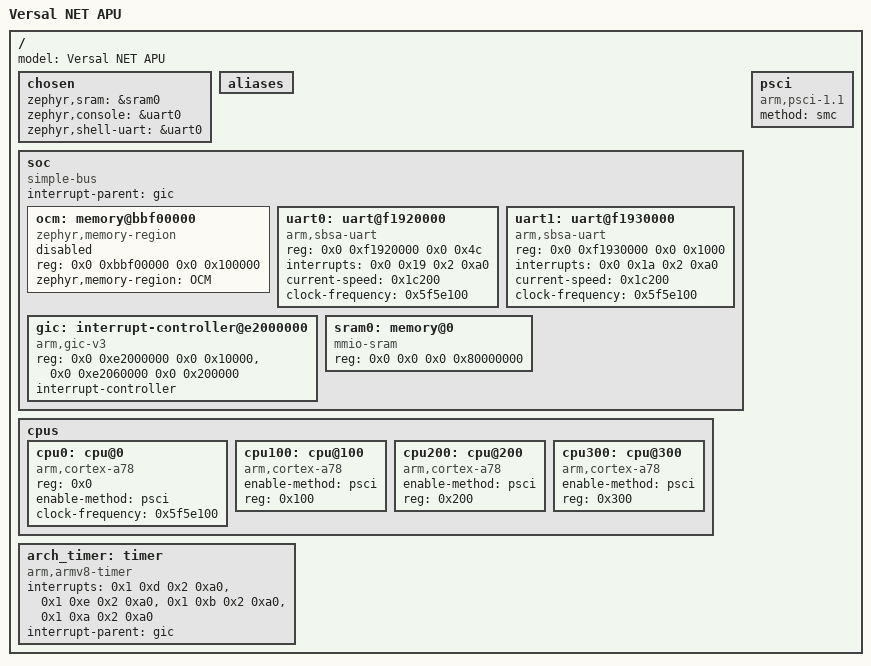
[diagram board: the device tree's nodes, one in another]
/dts-v1/;

/* node '/' defined in zephyr/dts/common/skeleton.dtsi:9 */
/ {
	model = "Versal NET APU"; /* in zephyr/dts/arm64/xilinx/versalnet_a78.dtsi:15 */
	#address-cells = < 0x2 >; /* in zephyr/dts/arm64/xilinx/versalnet_a78.dtsi:16 */
	#size-cells = < 0x2 >;    /* in zephyr/dts/arm64/xilinx/versalnet_a78.dtsi:17 */

	/* node '/chosen' defined in zephyr/dts/common/skeleton.dtsi:13 */
	chosen {
		zephyr,sram = &sram0;       /* in zephyr/boards/amd/versalnet_apu/versalnet_apu.dts:12 */
		zephyr,console = &uart0;    /* in zephyr/boards/amd/versalnet_apu/versalnet_apu.dts:13 */
		zephyr,shell-uart = &uart0; /* in zephyr/boards/amd/versalnet_apu/versalnet_apu.dts:14 */
	};

	/* node '/aliases' defined in zephyr/dts/common/skeleton.dtsi:15 */
	aliases {
	};

	/* node '/soc' defined in zephyr/dts/arm64/armv8-a.dtsi:10 */
	soc: soc {
		compatible = "simple-bus";   /* in zephyr/dts/arm64/armv8-a.dtsi:13 */
		ranges;                      /* in zephyr/dts/arm64/armv8-a.dtsi:14 */
		#address-cells = < 0x2 >;    /* in zephyr/dts/vendor/amd/versalnet_apu.dtsi:9 */
		#size-cells = < 0x2 >;       /* in zephyr/dts/vendor/amd/versalnet_apu.dtsi:10 */
		interrupt-parent = < &gic >; /* in zephyr/dts/arm64/xilinx/versalnet_a78.dtsi:68 */

		/* node '/soc/memory@bbf00000' defined in zephyr/dts/vendor/amd/versalnet_apu.dtsi:17 */
		ocm: memory@bbf00000 {
			compatible = "zephyr,memory-region";   /* in zephyr/dts/vendor/amd/versalnet_apu.dtsi:18 */
			reg = < 0x0 0xbbf00000 0x0 0x100000 >; /* in zephyr/dts/vendor/amd/versalnet_apu.dtsi:19 */
			status = "disabled";                   /* in zephyr/dts/vendor/amd/versalnet_apu.dtsi:20 */
			zephyr,memory-region = "OCM";          /* in zephyr/dts/vendor/amd/versalnet_apu.dtsi:21 */
		};

		/* node '/soc/uart@f1920000' defined in zephyr/dts/vendor/amd/versalnet_apu.dtsi:24 */
		uart0: uart@f1920000 {
			compatible = "arm,sbsa-uart";       /* in zephyr/dts/vendor/amd/versalnet_apu.dtsi:25 */
			reg = < 0x0 0xf1920000 0x0 0x4c >;  /* in zephyr/dts/vendor/amd/versalnet_apu.dtsi:26 */
			interrupt-names = "irq_0";          /* in zephyr/dts/vendor/amd/versalnet_apu.dtsi:28 */
			interrupts = < 0x0 0x19 0x2 0xa0 >; /* in zephyr/dts/vendor/amd/versalnet_apu.dtsi:29 */
			status = "okay";                    /* in zephyr/boards/amd/versalnet_apu/versalnet_apu.dts:36 */
			current-speed = < 0x1c200 >;        /* in zephyr/boards/amd/versalnet_apu/versalnet_apu.dts:37 */
			clock-frequency = < 0x5f5e100 >;    /* in zephyr/boards/amd/versalnet_apu/versalnet_apu.dts:38 */
		};

		/* node '/soc/uart@f1930000' defined in zephyr/dts/vendor/amd/versalnet_apu.dtsi:32 */
		uart1: uart@f1930000 {
			compatible = "arm,sbsa-uart";        /* in zephyr/dts/vendor/amd/versalnet_apu.dtsi:33 */
			reg = < 0x0 0xf1930000 0x0 0x1000 >; /* in zephyr/dts/vendor/amd/versalnet_apu.dtsi:34 */
			interrupt-names = "irq_1";           /* in zephyr/dts/vendor/amd/versalnet_apu.dtsi:36 */
			interrupts = < 0x0 0x1a 0x2 0xa0 >;  /* in zephyr/dts/vendor/amd/versalnet_apu.dtsi:37 */
			status = "okay";                     /* in zephyr/boards/amd/versalnet_apu/versalnet_apu.dts:30 */
			current-speed = < 0x1c200 >;         /* in zephyr/boards/amd/versalnet_apu/versalnet_apu.dts:31 */
			clock-frequency = < 0x5f5e100 >;     /* in zephyr/boards/amd/versalnet_apu/versalnet_apu.dts:32 */
		};

		/* node '/soc/interrupt-controller@e2000000' defined in zephyr/dts/arm64/xilinx/versalnet_a78.dtsi:70 */
		gic: interrupt-controller@e2000000 {
			compatible = "arm,gic-v3",
			             "arm,gic";                /* in zephyr/dts/arm64/xilinx/versalnet_a78.dtsi:71 */
			reg = < 0x0 0xe2000000 0x0 0x10000 >,
			      < 0x0 0xe2060000 0x0 0x200000 >; /* in zephyr/dts/arm64/xilinx/versalnet_a78.dtsi:72 */
			interrupt-controller;                  /* in zephyr/dts/arm64/xilinx/versalnet_a78.dtsi:74 */
			#interrupt-cells = < 0x4 >;            /* in zephyr/dts/arm64/xilinx/versalnet_a78.dtsi:75 */
			#address-cells = < 0x1 >;              /* in zephyr/dts/arm64/xilinx/versalnet_a78.dtsi:76 */
			#size-cells = < 0x1 >;                 /* in zephyr/dts/arm64/xilinx/versalnet_a78.dtsi:77 */
			phandle = < 0x1 >;                     /* in zephyr/dts/arm64/xilinx/versalnet_a78.dtsi:68 */
		};

		/* node '/soc/memory@0' defined in zephyr/boards/amd/versalnet_apu/versalnet_apu.dts:23 */
		sram0: memory@0 {
			compatible = "mmio-sram";         /* in zephyr/boards/amd/versalnet_apu/versalnet_apu.dts:24 */
			reg = < 0x0 0x0 0x0 0x80000000 >; /* in zephyr/boards/amd/versalnet_apu/versalnet_apu.dts:25 */
		};
	};

	/* node '/cpus' defined in zephyr/dts/arm64/xilinx/versalnet_a78.dtsi:19 */
	cpus {
		#address-cells = < 0x1 >; /* in zephyr/dts/arm64/xilinx/versalnet_a78.dtsi:20 */
		#size-cells = < 0x0 >;    /* in zephyr/dts/arm64/xilinx/versalnet_a78.dtsi:21 */

		/* node '/cpus/cpu@0' defined in zephyr/dts/arm64/xilinx/versalnet_a78.dtsi:23 */
		cpu0: cpu@0 {
			device_type = "cpu";             /* in zephyr/dts/arm64/xilinx/versalnet_a78.dtsi:24 */
			compatible = "arm,cortex-a78";   /* in zephyr/dts/arm64/xilinx/versalnet_a78.dtsi:25 */
			reg = < 0x0 >;                   /* in zephyr/dts/arm64/xilinx/versalnet_a78.dtsi:26 */
			enable-method = "psci";          /* in zephyr/dts/arm64/xilinx/versalnet_a78.dtsi:27 */
			clock-frequency = < 0x5f5e100 >; /* in zephyr/boards/amd/versalnet_apu/versalnet_apu.dts:19 */
		};

		/* node '/cpus/cpu@100' defined in zephyr/dts/arm64/xilinx/versalnet_a78.dtsi:30 */
		cpu100: cpu@100 {
			device_type = "cpu";           /* in zephyr/dts/arm64/xilinx/versalnet_a78.dtsi:31 */
			compatible = "arm,cortex-a78"; /* in zephyr/dts/arm64/xilinx/versalnet_a78.dtsi:32 */
			enable-method = "psci";        /* in zephyr/dts/arm64/xilinx/versalnet_a78.dtsi:33 */
			reg = < 0x100 >;               /* in zephyr/dts/arm64/xilinx/versalnet_a78.dtsi:34 */
		};

		/* node '/cpus/cpu@200' defined in zephyr/dts/arm64/xilinx/versalnet_a78.dtsi:37 */
		cpu200: cpu@200 {
			device_type = "cpu";           /* in zephyr/dts/arm64/xilinx/versalnet_a78.dtsi:38 */
			compatible = "arm,cortex-a78"; /* in zephyr/dts/arm64/xilinx/versalnet_a78.dtsi:39 */
			enable-method = "psci";        /* in zephyr/dts/arm64/xilinx/versalnet_a78.dtsi:40 */
			reg = < 0x200 >;               /* in zephyr/dts/arm64/xilinx/versalnet_a78.dtsi:41 */
		};

		/* node '/cpus/cpu@300' defined in zephyr/dts/arm64/xilinx/versalnet_a78.dtsi:44 */
		cpu300: cpu@300 {
			device_type = "cpu";           /* in zephyr/dts/arm64/xilinx/versalnet_a78.dtsi:45 */
			compatible = "arm,cortex-a78"; /* in zephyr/dts/arm64/xilinx/versalnet_a78.dtsi:46 */
			enable-method = "psci";        /* in zephyr/dts/arm64/xilinx/versalnet_a78.dtsi:47 */
			reg = < 0x300 >;               /* in zephyr/dts/arm64/xilinx/versalnet_a78.dtsi:48 */
		};
	};

	/* node '/psci' defined in zephyr/dts/arm64/xilinx/versalnet_a78.dtsi:52 */
	psci {
		compatible = "arm,psci-1.1"; /* in zephyr/dts/arm64/xilinx/versalnet_a78.dtsi:53 */
		method = "smc";              /* in zephyr/dts/arm64/xilinx/versalnet_a78.dtsi:54 */
	};

	/* node '/timer' defined in zephyr/dts/arm64/xilinx/versalnet_a78.dtsi:57 */
	arch_timer: timer {
		compatible = "arm,armv8-timer";    /* in zephyr/dts/arm64/xilinx/versalnet_a78.dtsi:58 */
		interrupts = < 0x1 0xd 0x2 0xa0 >,
		             < 0x1 0xe 0x2 0xa0 >,
		             < 0x1 0xb 0x2 0xa0 >,
		             < 0x1 0xa 0x2 0xa0 >; /* in zephyr/dts/arm64/xilinx/versalnet_a78.dtsi:59 */
		interrupt-parent = < &gic >;       /* in zephyr/dts/arm64/xilinx/versalnet_a78.dtsi:63 */
	};
};
